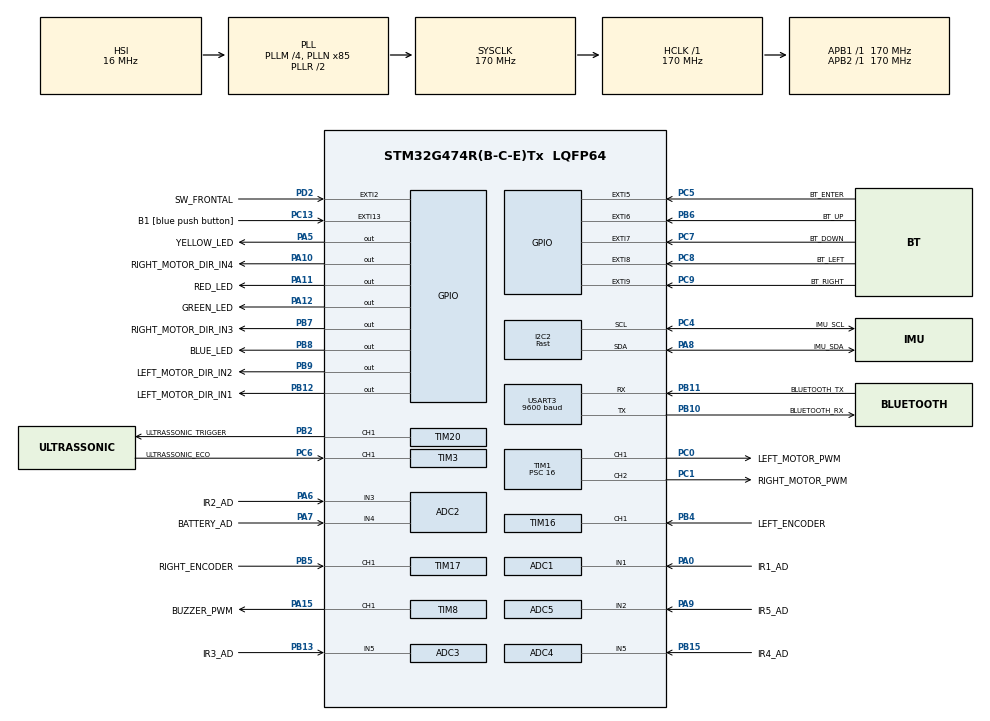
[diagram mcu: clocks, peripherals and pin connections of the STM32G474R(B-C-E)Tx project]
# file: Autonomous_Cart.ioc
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ADC1.Channel-2\#ChannelRegularConversion=ADC_CHANNEL_1
ADC1.ClockPrescaler=ADC_CLOCK_ASYNC_DIV256
ADC1.ContinuousConvMode=ENABLE
ADC1.DMAContinuousRequests=ENABLE
ADC1.NbrOfConversionFlag=1
ADC1.OffsetNumber-2\#ChannelRegularConversion=ADC_OFFSET_NONE
ADC1.Rank-2\#ChannelRegularConversion=1
ADC1.SamplingTime-2\#ChannelRegularConversion=ADC_SAMPLETIME_92CYCLES_5
ADC1.master=1
ADC2.Channel-0\#ChannelRegularConversion=ADC_CHANNEL_3
ADC2.Channel-1\#ChannelRegularConversion=ADC_CHANNEL_4
ADC2.ClockPrescaler=ADC_CLOCK_ASYNC_DIV256
ADC2.ContinuousConvMode=ENABLE
ADC2.DMAContinuousRequests=ENABLE
ADC2.NbrOfConversion=2
ADC2.NbrOfConversionFlag=1
ADC2.OffsetNumber-0\#ChannelRegularConversion=ADC_OFFSET_NONE
ADC2.OffsetNumber-1\#ChannelRegularConversion=ADC_OFFSET_NONE
ADC2.Rank-0\#ChannelRegularConversion=1
ADC2.Rank-1\#ChannelRegularConversion=2
ADC2.SamplingTime-0\#ChannelRegularConversion=ADC_SAMPLETIME_92CYCLES_5
ADC2.SamplingTime-1\#ChannelRegularConversion=ADC_SAMPLETIME_92CYCLES_5
ADC3.Channel-0\#ChannelRegularConversion=ADC_CHANNEL_5
ADC3.ClockPrescaler=ADC_CLOCK_ASYNC_DIV256
ADC3.ContinuousConvMode=ENABLE
ADC3.DMAContinuousRequests=ENABLE
ADC3.NbrOfConversionFlag=1
ADC3.OffsetNumber-0\#ChannelRegularConversion=ADC_OFFSET_NONE
ADC3.Rank-0\#ChannelRegularConversion=1
ADC3.SamplingTime-0\#ChannelRegularConversion=ADC_SAMPLETIME_92CYCLES_5
ADC3.master=1
ADC4.Channel-0\#ChannelRegularConversion=ADC_CHANNEL_5
ADC4.ClockPrescaler=ADC_CLOCK_ASYNC_DIV256
ADC4.ContinuousConvMode=ENABLE
ADC4.DMAContinuousRequests=ENABLE
ADC4.NbrOfConversionFlag=1
ADC4.OffsetNumber-0\#ChannelRegularConversion=ADC_OFFSET_NONE
ADC4.Rank-0\#ChannelRegularConversion=1
ADC4.SamplingTime-0\#ChannelRegularConversion=ADC_SAMPLETIME_92CYCLES_5
ADC5.Channel-0\#ChannelRegularConversion=ADC_CHANNEL_2
ADC5.ClockPrescaler=ADC_CLOCK_ASYNC_DIV256
ADC5.ContinuousConvMode=ENABLE
ADC5.DMAContinuousRequests=ENABLE
ADC5.NbrOfConversionFlag=1
ADC5.OffsetNumber-0\#ChannelRegularConversion=ADC_OFFSET_NONE
ADC5.Rank-0\#ChannelRegularConversion=1
ADC5.SamplingTime-0\#ChannelRegularConversion=ADC_SAMPLETIME_92CYCLES_5
Dma.ADC1.0.Direction=DMA_PERIPH_TO_MEMORY
Dma.ADC1.0.EventEnable=DISABLE
Dma.ADC1.0.Instance=DMA1_Channel1
Dma.ADC1.0.MemDataAlignment=DMA_MDATAALIGN_HALFWORD
Dma.ADC1.0.MemInc=DMA_MINC_ENABLE
Dma.ADC1.0.Mode=DMA_CIRCULAR
Dma.ADC1.0.PeriphDataAlignment=DMA_PDATAALIGN_HALFWORD
Dma.ADC1.0.PeriphInc=DMA_PINC_DISABLE
Dma.ADC1.0.Polarity=HAL_DMAMUX_REQ_GEN_RISING
Dma.ADC1.0.Priority=DMA_PRIORITY_LOW
Dma.ADC1.0.RequestNumber=1
Dma.ADC1.0.SignalID=NONE
Dma.ADC1.0.SyncEnable=DISABLE
Dma.ADC1.0.SyncPolarity=HAL_DMAMUX_SYNC_NO_EVENT
Dma.ADC1.0.SyncRequestNumber=1
Dma.ADC1.0.SyncSignalID=NONE
Dma.ADC2.1.Direction=DMA_PERIPH_TO_MEMORY
Dma.ADC2.1.EventEnable=DISABLE
Dma.ADC2.1.Instance=DMA1_Channel2
Dma.ADC2.1.MemDataAlignment=DMA_MDATAALIGN_HALFWORD
Dma.ADC2.1.MemInc=DMA_MINC_ENABLE
Dma.ADC2.1.Mode=DMA_CIRCULAR
Dma.ADC2.1.PeriphDataAlignment=DMA_PDATAALIGN_HALFWORD
Dma.ADC2.1.PeriphInc=DMA_PINC_DISABLE
Dma.ADC2.1.Polarity=HAL_DMAMUX_REQ_GEN_RISING
Dma.ADC2.1.Priority=DMA_PRIORITY_LOW
Dma.ADC2.1.RequestNumber=1
Dma.ADC2.1.SignalID=NONE
Dma.ADC2.1.SyncEnable=DISABLE
Dma.ADC2.1.SyncPolarity=HAL_DMAMUX_SYNC_NO_EVENT
Dma.ADC2.1.SyncRequestNumber=1
Dma.ADC2.1.SyncSignalID=NONE
Dma.ADC3.2.Direction=DMA_PERIPH_TO_MEMORY
Dma.ADC3.2.EventEnable=DISABLE
Dma.ADC3.2.Instance=DMA1_Channel3
Dma.ADC3.2.MemDataAlignment=DMA_MDATAALIGN_HALFWORD
Dma.ADC3.2.MemInc=DMA_MINC_ENABLE
Dma.ADC3.2.Mode=DMA_CIRCULAR
Dma.ADC3.2.PeriphDataAlignment=DMA_PDATAALIGN_HALFWORD
Dma.ADC3.2.PeriphInc=DMA_PINC_DISABLE
Dma.ADC3.2.Polarity=HAL_DMAMUX_REQ_GEN_RISING
Dma.ADC3.2.Priority=DMA_PRIORITY_LOW
Dma.ADC3.2.RequestNumber=1
Dma.ADC3.2.SignalID=NONE
Dma.ADC3.2.SyncEnable=DISABLE
Dma.ADC3.2.SyncPolarity=HAL_DMAMUX_SYNC_NO_EVENT
Dma.ADC3.2.SyncRequestNumber=1
Dma.ADC3.2.SyncSignalID=NONE
Dma.ADC4.3.Direction=DMA_PERIPH_TO_MEMORY
Dma.ADC4.3.EventEnable=DISABLE
Dma.ADC4.3.Instance=DMA1_Channel4
Dma.ADC4.3.MemDataAlignment=DMA_MDATAALIGN_HALFWORD
Dma.ADC4.3.MemInc=DMA_MINC_ENABLE
Dma.ADC4.3.Mode=DMA_CIRCULAR
Dma.ADC4.3.PeriphDataAlignment=DMA_PDATAALIGN_HALFWORD
Dma.ADC4.3.PeriphInc=DMA_PINC_DISABLE
Dma.ADC4.3.Polarity=HAL_DMAMUX_REQ_GEN_RISING
Dma.ADC4.3.Priority=DMA_PRIORITY_LOW
Dma.ADC4.3.RequestNumber=1
Dma.ADC4.3.SignalID=NONE
Dma.ADC4.3.SyncEnable=DISABLE
Dma.ADC4.3.SyncPolarity=HAL_DMAMUX_SYNC_NO_EVENT
Dma.ADC4.3.SyncRequestNumber=1
Dma.ADC4.3.SyncSignalID=NONE
Dma.ADC5.4.Direction=DMA_PERIPH_TO_MEMORY
Dma.ADC5.4.EventEnable=DISABLE
Dma.ADC5.4.Instance=DMA1_Channel5
Dma.ADC5.4.MemDataAlignment=DMA_MDATAALIGN_HALFWORD
Dma.ADC5.4.MemInc=DMA_MINC_ENABLE
Dma.ADC5.4.Mode=DMA_CIRCULAR
Dma.ADC5.4.PeriphDataAlignment=DMA_PDATAALIGN_HALFWORD
Dma.ADC5.4.PeriphInc=DMA_PINC_DISABLE
Dma.ADC5.4.Polarity=HAL_DMAMUX_REQ_GEN_RISING
Dma.ADC5.4.Priority=DMA_PRIORITY_LOW
Dma.ADC5.4.RequestNumber=1
Dma.ADC5.4.SignalID=NONE
Dma.ADC5.4.SyncEnable=DISABLE
Dma.ADC5.4.SyncPolarity=HAL_DMAMUX_SYNC_NO_EVENT
Dma.ADC5.4.SyncRequestNumber=1
Dma.ADC5.4.SyncSignalID=NONE
Dma.Request0=ADC1
Dma.Request1=ADC2
Dma.Request2=ADC3
Dma.Request3=ADC4
Dma.Request4=ADC5
I2C2.I2C_Speed_Mode=I2C_Fast
I2C2.Timing=0x10802D9B
Mcu.Family=STM32G4
Mcu.Name=STM32G474R(B-C-E)Tx
Mcu.Package=LQFP64
NVIC.EXTI15_10_IRQn=true\:1\:0\:true\:false\:true\:true\:true\:true
NVIC.EXTI2_IRQn=true\:0\:0\:false\:false\:true\:true\:true\:true
NVIC.PriorityGroup=NVIC_PRIORITYGROUP_4
NVIC.TIM1_TRG_COM_TIM17_IRQn=true\:0\:0\:false\:false\:true\:true\:true\:true
NVIC.TIM1_UP_TIM16_IRQn=true\:0\:0\:false\:false\:true\:true\:true\:true
NVIC.TIM2_IRQn=true\:2\:0\:true\:false\:true\:true\:true\:true
NVIC.TIM3_IRQn=true\:2\:0\:true\:false\:true\:true\:true\:true
NVIC.TIM4_IRQn=true\:2\:0\:true\:false\:true\:true\:true\:true
NVIC.USART3_IRQn=true\:0\:0\:false\:false\:true\:true\:true\:true
PA0.GPIO_Label=IR1_AD
PA0.Mode=IN1-Single-Ended
PA0.Signal=ADC1_IN1
PA10.GPIO_Label=RIGHT_MOTOR_DIR_IN4
PA10.Signal=GPIO_Output
PA11.GPIO_Label=RED_LED
PA11.Signal=GPIO_Output
PA12.GPIO_Label=GREEN_LED
PA12.Signal=GPIO_Output
PA13.GPIO_Label=T_SWDIO
PA13.Mode=Trace_Asynchronous_SW
PA13.Signal=SYS_JTMS-SWDIO
PA14.GPIO_Label=T_SWCLK
PA14.Mode=Trace_Asynchronous_SW
PA14.Signal=SYS_JTCK-SWCLK
PA15.GPIO_Label=BUZZER_PWM
PA15.Signal=S_TIM8_CH1
PA2.GPIO_Label=LPUART1_TX [STLINKV3E_VCP_RX]
PA2.Signal=LPUART1_TX
PA3.GPIO_Label=LPUART1_RX [STLINKV3E_VCP_TX]
PA3.Signal=LPUART1_RX
PA5.GPIO_Label=YELLOW_LED
PA5.Signal=GPIO_Output
PA6.GPIO_Label=IR2_AD
PA6.Mode=IN3-Single-Ended
PA6.Signal=ADC2_IN3
PA7.GPIO_Label=BATTERY_AD
PA7.Mode=IN4-Single-Ended
PA7.Signal=ADC2_IN4
PA8.GPIO_Label=IMU_SDA
PA8.Mode=I2C
PA8.Signal=I2C2_SDA
PA9.GPIO_Label=IR5_AD
PA9.Mode=IN2-Single-Ended
PA9.Signal=ADC5_IN2
PB10.GPIO_Label=BLUETOOTH_RX
PB10.Mode=Asynchronous
PB10.Signal=USART3_TX
PB11.GPIO_Label=BLUETOOTH_TX
PB11.Mode=Asynchronous
PB11.Signal=USART3_RX
PB12.GPIO_Label=LEFT_MOTOR_DIR_IN1
PB12.Signal=GPIO_Output
PB13.GPIO_Label=IR3_AD
PB13.Mode=IN5-Single-Ended
PB13.Signal=ADC3_IN5
PB15.GPIO_Label=IR4_AD
PB15.Mode=IN5-Single-Ended
PB15.Signal=ADC4_IN5
PB2.GPIO_Label=ULTRASSONIC_TRIGGER
PB2.Signal=S_TIM20_CH1
PB3.GPIO_Label=T_SWO
PB3.Mode=Trace_Asynchronous_SW
PB3.Signal=SYS_JTDO-SWO
PB4.GPIO_Label=LEFT_ENCODER
PB4.Signal=S_TIM16_CH1
PB5.GPIO_Label=RIGHT_ENCODER
PB5.Signal=S_TIM17_CH1
PB6.GPIO_Label=BT_UP
PB6.Signal=GPXTI6
PB7.GPIO_Label=RIGHT_MOTOR_DIR_IN3
PB7.Signal=GPIO_Output
PB8-BOOT0.GPIO_Label=BLUE_LED
PB8-BOOT0.Signal=GPIO_Output
PB9.GPIO_Label=LEFT_MOTOR_DIR_IN2
PB9.Signal=GPIO_Output
PC0.GPIO_Label=LEFT_MOTOR_PWM
PC0.Signal=S_TIM1_CH1
PC1.GPIO_Label=RIGHT_MOTOR_PWM
PC1.Signal=S_TIM1_CH2
PC13.GPIO_Label=B1 [blue push button]
PC13.Signal=GPXTI13
PC14-OSC32_IN.Mode=LSE-External-Oscillator
PC14-OSC32_IN.Signal=RCC_OSC32_IN
PC15-OSC32_OUT.Mode=LSE-External-Oscillator
PC15-OSC32_OUT.Signal=RCC_OSC32_OUT
PC4.GPIO_Label=IMU_SCL
PC4.Mode=I2C
PC4.Signal=I2C2_SCL
PC5.GPIO_Label=BT_ENTER
PC5.Signal=GPXTI5
PC6.GPIO_Label=ULTRASSONIC_ECO
PC6.Signal=S_TIM3_CH1
PC7.GPIO_Label=BT_DOWN
PC7.Signal=GPXTI7
PC8.GPIO_Label=BT_LEFT
PC8.Signal=GPXTI8
PC9.GPIO_Label=BT_RIGHT
PC9.Signal=GPXTI9
PD2.GPIO_Label=SW_FRONTAL
PD2.GPIO_ModeDefaultEXTI=GPIO_MODE_IT_FALLING
PD2.GPIO_PuPd=GPIO_PULLUP
PD2.Signal=GPXTI2
PF0-OSC_IN.Mode=HSE-External-Oscillator
PF0-OSC_IN.Signal=RCC_OSC_IN
PF1-OSC_OUT.Mode=HSE-External-Oscillator
PF1-OSC_OUT.Signal=RCC_OSC_OUT
ProjectManager.HeapSize=0x200
ProjectManager.StackSize=0x400
ProjectManager.TargetToolchain=STM32CubeIDE
RCC.ADC12Freq_Value=170000000
RCC.ADC345Freq_Value=170000000
RCC.AHBFreq_Value=170000000
RCC.APB1Freq_Value=170000000
RCC.APB1TimFreq_Value=170000000
RCC.APB2Freq_Value=170000000
RCC.APB2TimFreq_Value=170000000
RCC.CortexFreq_Value=170000000
RCC.EXTERNAL_CLOCK_VALUE=12288000
RCC.HCLKFreq_Value=170000000
RCC.HSE_VALUE=24000000
RCC.HSI48_VALUE=48000000
RCC.HSI_VALUE=16000000
RCC.PLLM=RCC_PLLM_DIV4
RCC.PLLN=85
RCC.RTCClockSelection=RCC_RTCCLKSOURCE_LSE
RCC.SYSCLKFreq_VALUE=170000000
RCC.SYSCLKSource=RCC_SYSCLKSOURCE_PLLCLK
RCC.USBFreq_Value=170000000
RCC.VCOOutputFreq_Value=340000000
SH.S_TIM16_CH1.0=TIM16_CH1,Input_Capture1_from_TI1
SH.S_TIM17_CH1.0=TIM17_CH1,Input_Capture1_from_TI1
SH.S_TIM1_CH1.0=TIM1_CH1,PWM Generation1 CH1
SH.S_TIM1_CH2.0=TIM1_CH2,PWM Generation2 CH2
SH.S_TIM20_CH1.0=TIM20_CH1,PWM Generation1 CH1
SH.S_TIM3_CH1.0=TIM3_CH1,Input_Capture1_from_TI1
SH.S_TIM8_CH1.0=TIM8_CH1,PWM Generation1 CH1
TIM1.Channel-PWM\ Generation1\ CH1=TIM_CHANNEL_1
TIM1.Channel-PWM\ Generation2\ CH2=TIM_CHANNEL_2
TIM1.PeriodNoDither=1000
TIM1.Prescaler=16
TIM16.Channel=TIM_CHANNEL_1
TIM16.ICFilter_CH1=15
TIM16.ICPolarity_CH1=TIM_INPUTCHANNELPOLARITY_BOTHEDGE
TIM16.PeriodNoDither=10000
TIM16.Prescaler=1700-1
TIM17.Channel=TIM_CHANNEL_1
TIM17.ICFilter_CH1=15
TIM17.ICPolarity_CH1=TIM_INPUTCHANNELPOLARITY_BOTHEDGE
TIM17.PeriodNoDither=10000
TIM17.Prescaler=1700-1
TIM2.PeriodNoDither=32691
TIM2.Prescaler=200
TIM20.Channel-PWM\ Generation1\ CH1=TIM_CHANNEL_1
TIM20.Prescaler=260-1
TIM3.Channel-Input_Capture1_from_TI1=TIM_CHANNEL_1
TIM3.ICPolarity_CH1=TIM_INPUTCHANNELPOLARITY_RISING
TIM3.PeriodNoDither=65535
TIM3.Prescaler=260-1
TIM4.PeriodNoDither=65383
TIM4.Prescaler=200
TIM8.Channel-PWM\ Generation1\ CH1=TIM_CHANNEL_1
TIM8.PeriodNoDither=16999
USART3.BaudRate=9600
USART3.VirtualMode-Asynchronous=VM_ASYNC
VP_SYS_VS_DBSignals.Mode=DisableDeadBatterySignals
VP_TIM16_VS_ClockSourceINT.Mode=Enable_Timer
VP_TIM17_VS_ClockSourceINT.Mode=Enable_Timer
VP_TIM1_VS_ClockSourceINT.Mode=Internal
VP_TIM2_VS_ClockSourceINT.Mode=Internal
VP_TIM4_VS_ClockSourceINT.Mode=Internal
board=NUCLEO-G474RE

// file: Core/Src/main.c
/* USER CODE BEGIN Header */
/**
  ******************************************************************************
  * @file           : main.c
  * @brief          : Main program body
  ******************************************************************************
  * @attention
  *
  * Copyright (c) 2024 STMicroelectronics.
  * All rights reserved.
  *
  * This software is licensed under terms that can be found in the LICENSE file
  * in the root directory of this software component.
  * If no LICENSE file comes with this software, it is provided AS-IS.
  *
  ******************************************************************************
  */
/* USER CODE END Header */
#include "main.h"
#include "adc.h"
#include "dma.h"
#include "i2c.h"
#include "tim.h"
#include "usart.h"
#include "gpio.h"

/* USER CODE BEGIN Includes */
#include "MissionSoftware.h"
#include "PowerTrainSystem.h"
#include "encoderSystem.h"
#include "BatteryVoltageSystem.h"
//#include "LineSensorSystem.h"

/* USER CODE END Includes */

/* USER CODE BEGIN PV */
unsigned char bRobotMode;
/* USER CODE END PV */

void SystemClock_Config(void);

int main(void)
{

  /* MCU Configuration--------------------------------------------------------*/

  /* Reset of all peripherals, Initializes the Flash interface and the Systick. */
   HAL_Init();

  /* Configure the system clock */
  SystemClock_Config();

  /* Initialize all configured peripherals */
  MX_GPIO_Init();
  MX_DMA_Init();
  MX_ADC1_Init();
  MX_ADC2_Init();
  MX_ADC3_Init();
  MX_TIM1_Init();
  MX_TIM16_Init();
  MX_TIM4_Init();
  MX_ADC4_Init();
  MX_ADC5_Init();
  MX_I2C2_Init();
  MX_TIM8_Init();
  MX_TIM17_Init();
  MX_TIM2_Init();
  MX_TIM3_Init();
  MX_TIM20_Init();
  MX_USART3_UART_Init();

  /* Infinite loop */
  /* USER CODE BEGIN WHILE */
  while (1)
  {

	  vMissionSoftwareMain();
    /* USER CODE END WHILE */

  }
}

void SystemClock_Config(void)
{
  RCC_OscInitTypeDef RCC_OscInitStruct = {0};
  RCC_ClkInitTypeDef RCC_ClkInitStruct = {0};

  /** Configure the main internal regulator output voltage
  */
  HAL_PWREx_ControlVoltageScaling(PWR_REGULATOR_VOLTAGE_SCALE1_BOOST);

  /** Initializes the RCC Oscillators according to the specified parameters
  * in the RCC_OscInitTypeDef structure.
  */
  RCC_OscInitStruct.OscillatorType = RCC_OSCILLATORTYPE_HSI;
  RCC_OscInitStruct.HSIState = RCC_HSI_ON;
  RCC_OscInitStruct.HSICalibrationValue = RCC_HSICALIBRATION_DEFAULT;
  RCC_OscInitStruct.PLL.PLLState = RCC_PLL_ON;
  RCC_OscInitStruct.PLL.PLLSource = RCC_PLLSOURCE_HSI;
  RCC_OscInitStruct.PLL.PLLM = RCC_PLLM_DIV4;
  RCC_OscInitStruct.PLL.PLLN = 85;
  RCC_OscInitStruct.PLL.PLLP = RCC_PLLP_DIV2;
  RCC_OscInitStruct.PLL.PLLQ = RCC_PLLQ_DIV2;
  RCC_OscInitStruct.PLL.PLLR = RCC_PLLR_DIV2;
  if (HAL_RCC_OscConfig(&RCC_OscInitStruct) != HAL_OK)
  {
    Error_Handler();
  }

  /** Initializes the CPU, AHB and APB buses clocks
  */
  RCC_ClkInitStruct.ClockType = RCC_CLOCKTYPE_HCLK|RCC_CLOCKTYPE_SYSCLK
                              |RCC_CLOCKTYPE_PCLK1|RCC_CLOCKTYPE_PCLK2;
  RCC_ClkInitStruct.SYSCLKSource = RCC_SYSCLKSOURCE_PLLCLK;
  RCC_ClkInitStruct.AHBCLKDivider = RCC_SYSCLK_DIV1;
  RCC_ClkInitStruct.APB1CLKDivider = RCC_HCLK_DIV1;
  RCC_ClkInitStruct.APB2CLKDivider = RCC_HCLK_DIV1;

  if (HAL_RCC_ClockConfig(&RCC_ClkInitStruct, FLASH_LATENCY_4) != HAL_OK)
  {
    Error_Handler();
  }
}

void Error_Handler(void)
{
  __disable_irq();
  while (1)
  {
  }
}
